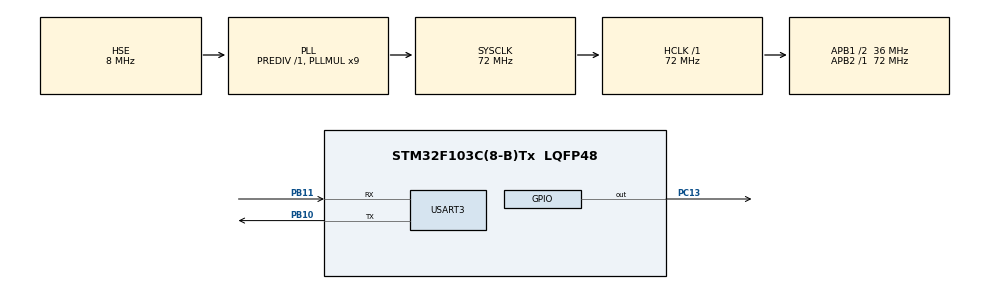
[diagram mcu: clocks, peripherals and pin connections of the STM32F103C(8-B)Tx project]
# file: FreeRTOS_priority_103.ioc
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FREERTOS.Tasks01=my_ON_Task,24,256,Start_ON_Task,Default,NULL,Dynamic,NULL,NULL;my_OFF_Task,24,256,Start_OFF_Task,Default,NULL,Dynamic,NULL,NULL
FREERTOS.configUSE_NEWLIB_REENTRANT=1
Mcu.Family=STM32F1
Mcu.Name=STM32F103C(8-B)Tx
Mcu.Package=LQFP48
NVIC.PriorityGroup=NVIC_PRIORITYGROUP_4
NVIC.TIM4_IRQn=true\:15\:0\:false\:false\:true\:false\:false\:true\:true
NVIC.TimeBase=TIM4_IRQn
NVIC.TimeBaseIP=TIM4
PA13.Mode=Serial_Wire
PA13.Signal=SYS_JTMS-SWDIO
PA14.Mode=Serial_Wire
PA14.Signal=SYS_JTCK-SWCLK
PB10.Mode=Asynchronous
PB10.Signal=USART3_TX
PB11.Mode=Asynchronous
PB11.Signal=USART3_RX
PC13-TAMPER-RTC.PinState=GPIO_PIN_SET
PC13-TAMPER-RTC.Signal=GPIO_Output
PD0-OSC_IN.Mode=HSE-External-Oscillator
PD0-OSC_IN.Signal=RCC_OSC_IN
PD1-OSC_OUT.Mode=HSE-External-Oscillator
PD1-OSC_OUT.Signal=RCC_OSC_OUT
ProjectManager.HeapSize=0x200
ProjectManager.StackSize=0x400
ProjectManager.TargetToolchain=STM32CubeIDE
RCC.AHBFreq_Value=72000000
RCC.APB1CLKDivider=RCC_HCLK_DIV2
RCC.APB1Freq_Value=36000000
RCC.APB1TimFreq_Value=72000000
RCC.APB2Freq_Value=72000000
RCC.APB2TimFreq_Value=72000000
RCC.HCLKFreq_Value=72000000
RCC.PLLMUL=RCC_PLL_MUL9
RCC.PLLSourceVirtual=RCC_PLLSOURCE_HSE
RCC.SYSCLKFreq_VALUE=72000000
RCC.SYSCLKSource=RCC_SYSCLKSOURCE_PLLCLK
RCC.USBFreq_Value=72000000
USART3.VirtualMode=VM_ASYNC
VP_FREERTOS_VS_CMSIS_V2.Mode=CMSIS_V2
VP_SYS_VS_tim4.Mode=TIM4
board=custom

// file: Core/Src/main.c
/* USER CODE BEGIN Header */
/**
 ******************************************************************************
 * @file           : main.c
 * @brief          : Main program body
 ******************************************************************************
 * @attention
 *
 * Copyright (c) 2023 STMicroelectronics.
 * All rights reserved.
 *
 * This software is licensed under terms that can be found in the LICENSE file
 * in the root directory of this software component.
 * If no LICENSE file comes with this software, it is provided AS-IS.
 *
 ******************************************************************************
 */
/* USER CODE END Header */
#include "main.h"
#include "cmsis_os.h"

/* USER CODE BEGIN Includes */
#include "stdbool.h"
#include <stdio.h>/* для printf */
#include "task.h"
/* USER CODE END Includes */

/* USER CODE BEGIN PTD */
bool flag;
uint8_t i = 0;
uint8_t k = 0;
unsigned long T;
/* USER CODE END PTD */

UART_HandleTypeDef huart3;

/* Definitions for my_ON_Task */
osThreadId_t my_ON_TaskHandle;
const osThreadAttr_t my_ON_Task_attributes = {
  .name = "my_ON_Task",
  .stack_size = 256 * 4,
  .priority = (osPriority_t) osPriorityNormal,
};
/* Definitions for my_OFF_Task */
osThreadId_t my_OFF_TaskHandle;
const osThreadAttr_t my_OFF_Task_attributes = {
  .name = "my_OFF_Task",
  .stack_size = 256 * 4,
  .priority = (osPriority_t) osPriorityNormal,
};

void SystemClock_Config(void);
static void MX_GPIO_Init(void);
static void MX_USART3_UART_Init(void);
void Start_ON_Task(void *argument);
void Start_OFF_Task(void *argument);

/* USER CODE BEGIN PFP */
int _write(int file, char *ptr, int len) {
	int i;
	HAL_UART_Transmit(&huart3, (uint8_t*) ptr, len, 50);
	for (i = 0; i < len; i++) {
		ITM_SendChar(*ptr++);
	}
	return len;
}
/* USER CODE END PFP */

int main(void)
{

  /* MCU Configuration--------------------------------------------------------*/

  /* Reset of all peripherals, Initializes the Flash interface and the Systick. */
  HAL_Init();

  /* USER CODE BEGIN Init */
	T = HAL_GetTick();
	flag = 1;
  /* USER CODE END Init */

  /* Configure the system clock */
  SystemClock_Config();

  /* Initialize all configured peripherals */
  MX_GPIO_Init();
  MX_USART3_UART_Init();

  /* Init scheduler */
  osKernelInitialize();

  /* Create the thread(s) */
  /* creation of my_ON_Task */
  my_ON_TaskHandle = osThreadNew(Start_ON_Task, NULL, &my_ON_Task_attributes);

  /* creation of my_OFF_Task */
  my_OFF_TaskHandle = osThreadNew(Start_OFF_Task, NULL, &my_OFF_Task_attributes);

  /* Start scheduler */
  osKernelStart();

  /* We should never get here as control is now taken by the scheduler */
  /* Infinite loop */
	while (1) {

	}
}

void SystemClock_Config(void)
{
  RCC_OscInitTypeDef RCC_OscInitStruct = {0};
  RCC_ClkInitTypeDef RCC_ClkInitStruct = {0};

  /** Initializes the RCC Oscillators according to the specified parameters
  * in the RCC_OscInitTypeDef structure.
  */
  RCC_OscInitStruct.OscillatorType = RCC_OSCILLATORTYPE_HSE;
  RCC_OscInitStruct.HSEState = RCC_HSE_ON;
  RCC_OscInitStruct.HSEPredivValue = RCC_HSE_PREDIV_DIV1;
  RCC_OscInitStruct.HSIState = RCC_HSI_ON;
  RCC_OscInitStruct.PLL.PLLState = RCC_PLL_ON;
  RCC_OscInitStruct.PLL.PLLSource = RCC_PLLSOURCE_HSE;
  RCC_OscInitStruct.PLL.PLLMUL = RCC_PLL_MUL9;
  if (HAL_RCC_OscConfig(&RCC_OscInitStruct) != HAL_OK)
  {
    Error_Handler();
  }

  /** Initializes the CPU, AHB and APB buses clocks
  */
  RCC_ClkInitStruct.ClockType = RCC_CLOCKTYPE_HCLK|RCC_CLOCKTYPE_SYSCLK
                              |RCC_CLOCKTYPE_PCLK1|RCC_CLOCKTYPE_PCLK2;
  RCC_ClkInitStruct.SYSCLKSource = RCC_SYSCLKSOURCE_PLLCLK;
  RCC_ClkInitStruct.AHBCLKDivider = RCC_SYSCLK_DIV1;
  RCC_ClkInitStruct.APB1CLKDivider = RCC_HCLK_DIV2;
  RCC_ClkInitStruct.APB2CLKDivider = RCC_HCLK_DIV1;

  if (HAL_RCC_ClockConfig(&RCC_ClkInitStruct, FLASH_LATENCY_2) != HAL_OK)
  {
    Error_Handler();
  }
}

static void MX_USART3_UART_Init(void)
{

  huart3.Instance = USART3;
  huart3.Init.BaudRate = 115200;
  huart3.Init.WordLength = UART_WORDLENGTH_8B;
  huart3.Init.StopBits = UART_STOPBITS_1;
  huart3.Init.Parity = UART_PARITY_NONE;
  huart3.Init.Mode = UART_MODE_TX_RX;
  huart3.Init.HwFlowCtl = UART_HWCONTROL_NONE;
  huart3.Init.OverSampling = UART_OVERSAMPLING_16;
  if (HAL_UART_Init(&huart3) != HAL_OK)
  {
    Error_Handler();
  }

}

static void MX_GPIO_Init(void)
{
  GPIO_InitTypeDef GPIO_InitStruct = {0};

  /* GPIO Ports Clock Enable */
  __HAL_RCC_GPIOC_CLK_ENABLE();
  __HAL_RCC_GPIOD_CLK_ENABLE();
  __HAL_RCC_GPIOB_CLK_ENABLE();
  __HAL_RCC_GPIOA_CLK_ENABLE();

  /*Configure GPIO pin Output Level */
  HAL_GPIO_WritePin(GPIOC, GPIO_PIN_13, GPIO_PIN_SET);

  /*Configure GPIO pin : PC13 */
  GPIO_InitStruct.Pin = GPIO_PIN_13;
  GPIO_InitStruct.Mode = GPIO_MODE_OUTPUT_PP;
  GPIO_InitStruct.Pull = GPIO_NOPULL;
  GPIO_InitStruct.Speed = GPIO_SPEED_FREQ_LOW;
  HAL_GPIO_Init(GPIOC, &GPIO_InitStruct);

}

void Start_ON_Task(void *argument)
{
  /* USER CODE BEGIN 5 */
	/* Infinite loop */
	for (;;) {
		if (flag == 1) {
			if (HAL_GetTick() - T >= 250) {
				flag = 0;
				T = HAL_GetTick();
				printf("LED is ON \r\n");
			}
		}
		HAL_GPIO_WritePin(GPIOC, GPIO_PIN_13, flag);
		//osDelay(1);
	}
  /* USER CODE END 5 */
}

void Start_OFF_Task(void *argument)
{
  /* USER CODE BEGIN Start_OFF_Task */
	/* Infinite loop */
	for (;;) {
		if (uxTaskPriorityGet(my_ON_TaskHandle) == osPriorityLow) {
			printf("'ON_Task' has priority is 'LOW' k =  %d\r\n", k);
			if (k >=5) {
				vTaskPrioritySet(my_ON_TaskHandle, osPriorityNormal);
				k = 0;
			}
			k++;
			osDelay(500);
		} else {

			if (flag == 0) {
				if (HAL_GetTick() - T >= 250) {
					flag = 1;
					T = HAL_GetTick();
					printf("LED is OFF %d\r\n",i);
					if (i >=5) {
						vTaskPrioritySet(my_ON_TaskHandle, osPriorityLow);
						i = 0;
					}
					i++;
				}
			}
			HAL_GPIO_WritePin(GPIOC, GPIO_PIN_13, flag);
			//osDelay(1);
		}
	}
  /* USER CODE END Start_OFF_Task */
}

void HAL_TIM_PeriodElapsedCallback(TIM_HandleTypeDef *htim)
{
  if (htim->Instance == TIM4) {
    HAL_IncTick();
  }
}

void Error_Handler(void)
{
	__disable_irq();
	while (1) {
	}
}
